VERSION "berumiya 990S labo"
CM_ "License: CC-BY 4.0";
CM_ "Repository : https://github.com/berumiya/CAN_DBC_6thGenMazda";
CM_ "Decoded and maintained by berumiya 990S labo";
CM_ "Source : reverse-engineered CAN traffic.";

NS_ :

BS_:
BU_: UART_SSU UART_BCMM
BO_ 010 UART_SSU: 8 UART_SSU

BO_ 012 UART_SSU: 8 UART_SSU

BO_ 178 UART_SSU: 8 UART_SSU

BO_ 180 UART_SSU: 8 UART_SSU

BO_ 181 UART_SSU: 8 UART_SSU

BO_ 011 UART_BCMM: 8 UART_BCMM

BO_ 013 UART_BCMM: 8 UART_BCMM

BO_ 089 UART_BCMM: 8 UART_BCMM

BO_ 218 UART_BCMM: 8 UART_BCMM

BO_ 220 UART_BCMM: 8 UART_BCMM

BO_ 221 UART_BCMM: 8 UART_BCMM

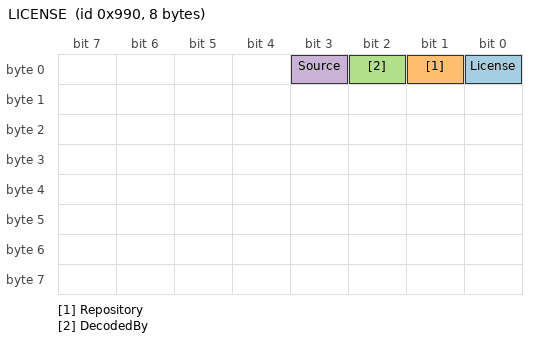
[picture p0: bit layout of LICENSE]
BO_ 2448 LICENSE: 8 LICENSE
   SG_ License : 0|1@0+ (1,0) [0|1] "License: CC-BY 4.0" Vector__XXX
   SG_ Repository : 1|1@0+ (1,0) [0|1] "https://github.com/berumiya/CAN_DBC_6thGenMazda" Vector__XXX
   SG_ DecodedBy : 2|1@0+ (1,0) [0|1] "Decoded and maintained by berumiya 990S labo" Vector__XXX
   SG_ Source : 3|1@0+ (1,0) [0|1] "reverse-engineered CAN traffic." Vector__XXX
